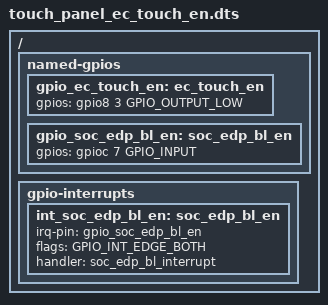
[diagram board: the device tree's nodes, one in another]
/* Copyright 2026 The ChromiumOS Authors
 * Use of this source code is governed by a BSD-style license that can be
 * found in the LICENSE file.
 */

#include "generic_npcx.dts"

/ {
	named-gpios {
		gpio_ec_touch_en: ec_touch_en {
			gpios = <&gpio8 3 GPIO_OUTPUT_LOW>;
		};
		gpio_soc_edp_bl_en: soc_edp_bl_en {
			gpios = <&gpioc 7 GPIO_INPUT>;
		};
	};

	gpio-interrupts {
		int_soc_edp_bl_en: soc_edp_bl_en {
			irq-pin = <&gpio_soc_edp_bl_en>;
			flags = <GPIO_INT_EDGE_BOTH>;
			handler = "soc_edp_bl_interrupt";
		};
	};
};
